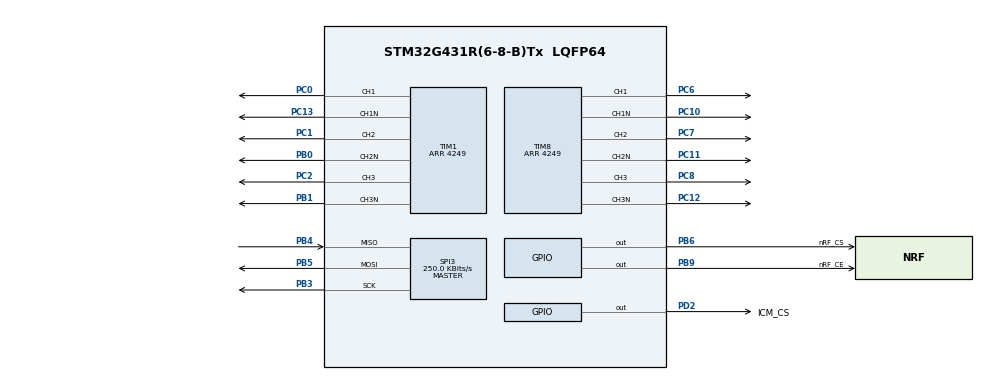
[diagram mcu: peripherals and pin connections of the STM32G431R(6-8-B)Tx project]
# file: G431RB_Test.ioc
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Dma.Request0=SPI3_RX
Dma.Request1=SPI3_TX
Dma.SPI3_RX.0.Direction=DMA_PERIPH_TO_MEMORY
Dma.SPI3_RX.0.EventEnable=DISABLE
Dma.SPI3_RX.0.Instance=DMA1_Channel1
Dma.SPI3_RX.0.MemDataAlignment=DMA_MDATAALIGN_BYTE
Dma.SPI3_RX.0.MemInc=DMA_MINC_ENABLE
Dma.SPI3_RX.0.Mode=DMA_NORMAL
Dma.SPI3_RX.0.PeriphDataAlignment=DMA_PDATAALIGN_BYTE
Dma.SPI3_RX.0.PeriphInc=DMA_PINC_DISABLE
Dma.SPI3_RX.0.Polarity=HAL_DMAMUX_REQ_GEN_RISING
Dma.SPI3_RX.0.Priority=DMA_PRIORITY_VERY_HIGH
Dma.SPI3_RX.0.RequestNumber=1
Dma.SPI3_RX.0.SignalID=NONE
Dma.SPI3_RX.0.SyncEnable=DISABLE
Dma.SPI3_RX.0.SyncPolarity=HAL_DMAMUX_SYNC_NO_EVENT
Dma.SPI3_RX.0.SyncRequestNumber=1
Dma.SPI3_RX.0.SyncSignalID=NONE
Dma.SPI3_TX.1.Direction=DMA_MEMORY_TO_PERIPH
Dma.SPI3_TX.1.EventEnable=DISABLE
Dma.SPI3_TX.1.Instance=DMA1_Channel2
Dma.SPI3_TX.1.MemDataAlignment=DMA_MDATAALIGN_BYTE
Dma.SPI3_TX.1.MemInc=DMA_MINC_ENABLE
Dma.SPI3_TX.1.Mode=DMA_NORMAL
Dma.SPI3_TX.1.PeriphDataAlignment=DMA_PDATAALIGN_BYTE
Dma.SPI3_TX.1.PeriphInc=DMA_PINC_DISABLE
Dma.SPI3_TX.1.Polarity=HAL_DMAMUX_REQ_GEN_RISING
Dma.SPI3_TX.1.Priority=DMA_PRIORITY_VERY_HIGH
Dma.SPI3_TX.1.RequestNumber=1
Dma.SPI3_TX.1.SignalID=NONE
Dma.SPI3_TX.1.SyncEnable=DISABLE
Dma.SPI3_TX.1.SyncPolarity=HAL_DMAMUX_SYNC_NO_EVENT
Dma.SPI3_TX.1.SyncRequestNumber=1
Dma.SPI3_TX.1.SyncSignalID=NONE
Mcu.Family=STM32G4
Mcu.Name=STM32G431R(6-8-B)Tx
Mcu.Package=LQFP64
NVIC.DMA1_Channel1_IRQn=true\:0\:0\:false\:false\:true\:false\:true\:true
NVIC.DMA1_Channel2_IRQn=true\:0\:0\:false\:false\:true\:false\:true\:true
NVIC.PriorityGroup=NVIC_PRIORITYGROUP_4
PA13.Mode=Serial_Wire
PA13.Signal=SYS_JTMS-SWDIO
PA14.Mode=Serial_Wire
PA14.Signal=SYS_JTCK-SWCLK
PB0.Mode=PWM Generation2 CH2 CH2N
PB0.Signal=TIM1_CH2N
PB1.Mode=PWM Generation3 CH3 CH3N
PB1.Signal=TIM1_CH3N
PB3.Mode=Full_Duplex_Master
PB3.Signal=SPI3_SCK
PB4.Mode=Full_Duplex_Master
PB4.Signal=SPI3_MISO
PB5.Mode=Full_Duplex_Master
PB5.Signal=SPI3_MOSI
PB6.GPIO_Label=nRF_CS
PB6.Signal=GPIO_Output
PB9.GPIO_Label=nRF_CE
PB9.Signal=GPIO_Output
PC0.Signal=S_TIM1_CH1
PC1.Signal=S_TIM1_CH2
PC10.Mode=PWM Generation1 CH1 CH1N
PC10.Signal=TIM8_CH1N
PC11.Mode=PWM Generation2 CH2 CH2N
PC11.Signal=TIM8_CH2N
PC12.Mode=PWM Generation3 CH3 CH3N
PC12.Signal=TIM8_CH3N
PC13.Mode=PWM Generation1 CH1 CH1N
PC13.Signal=TIM1_CH1N
PC2.Signal=S_TIM1_CH3
PC6.Signal=S_TIM8_CH1
PC7.Signal=S_TIM8_CH2
PC8.Signal=S_TIM8_CH3
PD2.GPIO_Label=ICM_CS
PD2.Signal=GPIO_Output
PF0-OSC_IN.Mode=HSE-External-Oscillator
PF0-OSC_IN.Signal=RCC_OSC_IN
PF1-OSC_OUT.Mode=HSE-External-Oscillator
PF1-OSC_OUT.Signal=RCC_OSC_OUT
ProjectManager.HeapSize=0x200
ProjectManager.StackSize=0x400
ProjectManager.TargetToolchain=CMake
RCC.HSE_VALUE=16000000
RCC.PLLSourceVirtual=RCC_PLLSOURCE_HSE
RCC.SYSCLKSource=RCC_SYSCLKSOURCE_PLLCLK
SH.S_TIM1_CH1.0=TIM1_CH1,PWM Generation1 CH1 CH1N
SH.S_TIM1_CH2.0=TIM1_CH2,PWM Generation2 CH2 CH2N
SH.S_TIM1_CH3.0=TIM1_CH3,PWM Generation3 CH3 CH3N
SH.S_TIM8_CH1.0=TIM8_CH1,PWM Generation1 CH1 CH1N
SH.S_TIM8_CH2.0=TIM8_CH2,PWM Generation2 CH2 CH2N
SH.S_TIM8_CH3.0=TIM8_CH3,PWM Generation3 CH3 CH3N
SPI3.BaudRatePrescaler=SPI_BAUDRATEPRESCALER_16
SPI3.CRCCalculation=SPI_CRCCALCULATION_DISABLE
SPI3.CalculateBaudRate=250.0 KBits/s
SPI3.DataSize=SPI_DATASIZE_8BIT
SPI3.Direction=SPI_DIRECTION_2LINES
SPI3.Mode=SPI_MODE_MASTER
SPI3.NSSPMode=SPI_NSS_PULSE_DISABLE
SPI3.VirtualType=VM_MASTER
TIM1.AutoReloadPreload=TIM_AUTORELOAD_PRELOAD_ENABLE
TIM1.AutomaticOutput=TIM_AUTOMATICOUTPUT_ENABLE
TIM1.Channel-PWM\ Generation1\ CH1\ CH1N=TIM_CHANNEL_1
TIM1.Channel-PWM\ Generation2\ CH2\ CH2N=TIM_CHANNEL_2
TIM1.Channel-PWM\ Generation3\ CH3\ CH3N=TIM_CHANNEL_3
TIM1.Channel-PWM\ Generation4\ No\ Output=TIM_CHANNEL_4
TIM1.CounterMode=TIM_COUNTERMODE_CENTERALIGNED1
TIM1.DeadTime=5
TIM1.DeadTimePreload=ENABLE
TIM1.OffStateIDLEMode=TIM_OSSI_ENABLE
TIM1.OffStateRunMode=TIM_OSSR_ENABLE
TIM1.PeriodNoDither=4249
TIM8.AutoReloadPreload=TIM_AUTORELOAD_PRELOAD_ENABLE
TIM8.AutomaticOutput=TIM_AUTOMATICOUTPUT_ENABLE
TIM8.Channel-PWM\ Generation1\ CH1\ CH1N=TIM_CHANNEL_1
TIM8.Channel-PWM\ Generation2\ CH2\ CH2N=TIM_CHANNEL_2
TIM8.Channel-PWM\ Generation3\ CH3\ CH3N=TIM_CHANNEL_3
TIM8.Channel-PWM\ Generation4\ No\ Output=TIM_CHANNEL_4
TIM8.CounterMode=TIM_COUNTERMODE_CENTERALIGNED1
TIM8.DeadTime=5
TIM8.DeadTimePreload=ENABLE
TIM8.OCFastMode_PWM-PWM\ Generation1\ CH1\ CH1N=TIM_OCFAST_ENABLE
TIM8.OCFastMode_PWM-PWM\ Generation2\ CH2\ CH2N=TIM_OCFAST_ENABLE
TIM8.OCFastMode_PWM-PWM\ Generation3\ CH3\ CH3N=TIM_OCFAST_ENABLE
TIM8.OffStateIDLEMode=TIM_OSSI_ENABLE
TIM8.OffStateRunMode=TIM_OSSR_ENABLE
TIM8.PeriodNoDither=4249
VP_SYS_VS_DBSignals.Mode=DisableDeadBatterySignals
VP_TIM1_VS_ClockSourceINT.Mode=Internal
VP_TIM1_VS_no_output4.Mode=PWM Generation4 No Output
VP_TIM8_VS_ClockSourceINT.Mode=Internal
VP_TIM8_VS_no_output4.Mode=PWM Generation4 No Output
board=custom

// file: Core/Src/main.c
/* USER CODE BEGIN Header */
/**
  ******************************************************************************
  * @file           : main.c
  * @brief          : Main program body
  ******************************************************************************
  * @attention
  *
  * Copyright (c) 2026 STMicroelectronics.
  * All rights reserved.
  *
  * This software is licensed under terms that can be found in the LICENSE file
  * in the root directory of this software component.
  * If no LICENSE file comes with this software, it is provided AS-IS.
  *
  ******************************************************************************
  */
/* USER CODE END Header */
#include "main.h"
#include "dma.h"
#include "spi.h"
#include "tim.h"
#include "gpio.h"

/* USER CODE BEGIN Includes */
#include "nRF24.h"
#include "stm32g4xx_hal.h"
/* USER CODE END Includes */

/* USER CODE BEGIN PTD */
/* nRF24对象 */
nRF24_t nRF24L01_Handle;
/* USER CODE END PTD */

/* USER CODE BEGIN PV */
uint8_t RecData0[5];
nRF24_Status_t Err;
uint32_t Successed = 0;
/* USER CODE END PV */

void SystemClock_Config(void);

int main(void)
{

  /* MCU Configuration--------------------------------------------------------*/

  /* Reset of all peripherals, Initializes the Flash interface and the Systick. */
  HAL_Init();

  /* Configure the system clock */
  SystemClock_Config();

  /* Initialize all configured peripherals */
  MX_GPIO_Init();
  MX_DMA_Init();
  MX_SPI3_Init();
  MX_TIM1_Init();
  MX_TIM8_Init();
  /* USER CODE BEGIN 2 */

  /*= initi Timer =*/
  TIM8_SetUp();
  TIM8_SetCCRx(1000, 0, 0);

  /*= initi nRF24L01 =*/
  while (nRF24_Object_Handle(&nRF24L01_Handle, &hspi3) == Error );
  while (nRF24_Init(&nRF24L01_Handle) == Error);
  while (nRF24_RecMode(&nRF24L01_Handle) == Error);

  HAL_Delay(100);
  HAL_Delay(100);
  /* USER CODE END 2 */

  /* Infinite loop */
  while (1)
  {
    Err = nRF24_RecData(&nRF24L01_Handle, RecData0, 4);
    if (Err == Rec_Complete) Successed++;
  }
}

void SystemClock_Config(void)
{
  RCC_OscInitTypeDef RCC_OscInitStruct = {0};
  RCC_ClkInitTypeDef RCC_ClkInitStruct = {0};

  /** Configure the main internal regulator output voltage
  */
  HAL_PWREx_ControlVoltageScaling(PWR_REGULATOR_VOLTAGE_SCALE1);

  /** Initializes the RCC Oscillators according to the specified parameters
  * in the RCC_OscInitTypeDef structure.
  */
  RCC_OscInitStruct.OscillatorType = RCC_OSCILLATORTYPE_HSE;
  RCC_OscInitStruct.HSEState = RCC_HSE_ON;
  RCC_OscInitStruct.PLL.PLLState = RCC_PLL_ON;
  RCC_OscInitStruct.PLL.PLLSource = RCC_PLLSOURCE_HSE;
  RCC_OscInitStruct.PLL.PLLM = RCC_PLLM_DIV1;
  RCC_OscInitStruct.PLL.PLLN = 8;
  RCC_OscInitStruct.PLL.PLLP = RCC_PLLP_DIV2;
  RCC_OscInitStruct.PLL.PLLQ = RCC_PLLQ_DIV2;
  RCC_OscInitStruct.PLL.PLLR = RCC_PLLR_DIV2;
  if (HAL_RCC_OscConfig(&RCC_OscInitStruct) != HAL_OK)
  {
    Error_Handler();
  }

  /** Initializes the CPU, AHB and APB buses clocks
  */
  RCC_ClkInitStruct.ClockType = RCC_CLOCKTYPE_HCLK|RCC_CLOCKTYPE_SYSCLK
                              |RCC_CLOCKTYPE_PCLK1|RCC_CLOCKTYPE_PCLK2;
  RCC_ClkInitStruct.SYSCLKSource = RCC_SYSCLKSOURCE_PLLCLK;
  RCC_ClkInitStruct.AHBCLKDivider = RCC_SYSCLK_DIV1;
  RCC_ClkInitStruct.APB1CLKDivider = RCC_HCLK_DIV1;
  RCC_ClkInitStruct.APB2CLKDivider = RCC_HCLK_DIV1;

  if (HAL_RCC_ClockConfig(&RCC_ClkInitStruct, FLASH_LATENCY_0) != HAL_OK)
  {
    Error_Handler();
  }
}

void Error_Handler(void)
{
  __disable_irq();
  while (1)
  {
  }
}
